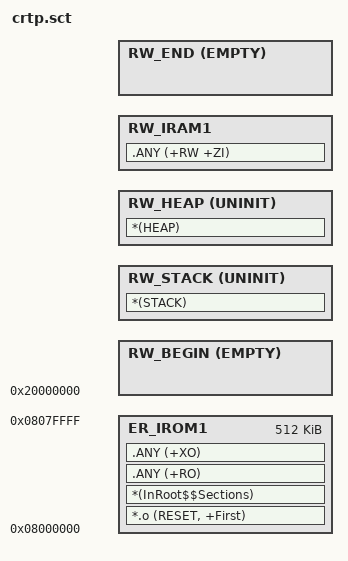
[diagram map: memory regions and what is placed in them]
; *************************************************************
; *** Scatter-Loading Description File generated by uVision ***
; *************************************************************

LR_IROM1 0x08000000 0x00080000  { ; load region size_region
  ER_IROM1 0x08000000 0x00080000  { ; load address = execution address
   *.o (RESET, +First)
   *(InRoot$$Sections)
   .ANY (+RO)
   .ANY (+XO)
  }
  RW_BEGIN  0x20000000 EMPTY 0 {
  }
  RW_STACK +0 UNINIT { ; Stack region growing down
    *(STACK)
  }
  RW_HEAP +0 UNINIT { ; We have to define heap region, even if we don't actually use heap
    *(HEAP)
  }
  RW_IRAM1 +0  { ; RW data
   .ANY (+RW +ZI)
  }
  RW_END ImageBase(RW_BEGIN) + 0x00020000 EMPTY 0 {
  }
}
